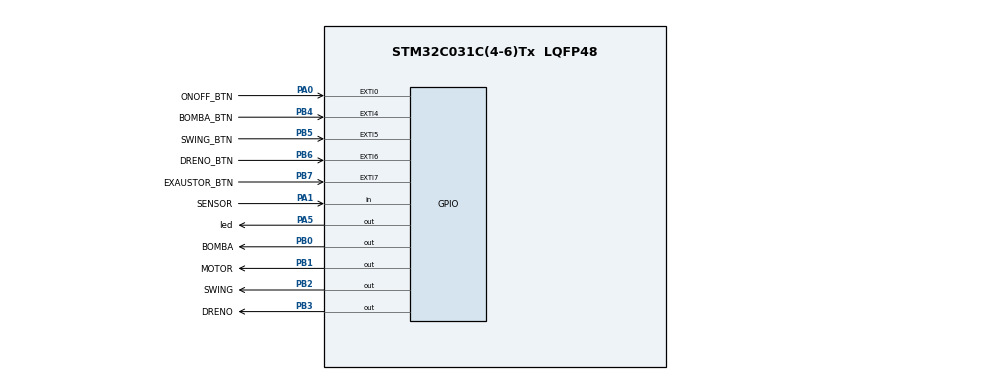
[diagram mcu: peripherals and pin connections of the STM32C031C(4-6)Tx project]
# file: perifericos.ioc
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Mcu.Family=STM32C0
Mcu.Name=STM32C031C(4-6)Tx
Mcu.Package=LQFP48
NVIC.EXTI0_1_IRQn=true\:0\:0\:false\:false\:true\:true\:true\:true
NVIC.EXTI4_15_IRQn=true\:0\:0\:false\:false\:true\:true\:true\:true
NVIC.TIM14_IRQn=true\:0\:0\:false\:false\:true\:true\:true\:true
PA0.GPIO_Label=ONOFF_BTN
PA0.GPIO_PuPd=GPIO_PULLDOWN
PA0.Signal=GPXTI0
PA1.GPIO_Label=SENSOR
PA1.GPIO_PuPd=GPIO_PULLDOWN
PA1.Signal=GPIO_Input
PA13.GPIO_Label=DEBUG_SWDIO
PA13.Signal=DEBUG_SWDIO
PA14-BOOT0.GPIO_Label=DEBUG_SWCLK
PA14-BOOT0.Signal=DEBUG_SWCLK
PA2.GPIO_Label=VCP_USART2_TX
PA2.Signal=USART2_TX
PA3.GPIO_Label=VCP_USART2_RX
PA3.Signal=USART2_RX
PA5.GPIO_Label=led
PA5.GPIO_ModeDefaultOutputPP=GPIO_MODE_OUTPUT_PP
PA5.GPIO_PuPd=GPIO_PULLDOWN
PA5.GPIO_Speed=GPIO_SPEED_FREQ_VERY_HIGH
PA5.Signal=GPIO_Output
PB0.GPIO_Label=BOMBA
PB0.GPIO_PuPd=GPIO_PULLDOWN
PB0.Signal=GPIO_Output
PB1.GPIO_Label=MOTOR
PB1.GPIO_PuPd=GPIO_PULLDOWN
PB1.Signal=GPIO_Output
PB2.GPIO_Label=SWING
PB2.GPIO_PuPd=GPIO_PULLDOWN
PB2.Signal=GPIO_Output
PB3.GPIO_Label=DRENO
PB3.GPIO_PuPd=GPIO_PULLDOWN
PB3.Signal=GPIO_Output
PB4.GPIO_Label=BOMBA_BTN
PB4.GPIO_PuPd=GPIO_PULLDOWN
PB4.Signal=GPXTI4
PB5.GPIO_Label=SWING_BTN
PB5.GPIO_PuPd=GPIO_PULLDOWN
PB5.Signal=GPXTI5
PB6.GPIO_Label=DRENO_BTN
PB6.GPIO_PuPd=GPIO_PULLDOWN
PB6.Signal=GPXTI6
PB7.GPIO_Label=EXAUSTOR_BTN
PB7.GPIO_PuPd=GPIO_PULLDOWN
PB7.Signal=GPXTI7
PC14-OSCX_IN\ (PC14).GPIO_Label=RCC_OSCX_IN
PC14-OSCX_IN\ (PC14).Mode=LSE-External-Oscillator
PC14-OSCX_IN\ (PC14).Signal=RCC_OSCX_IN
PC15-OSCX_OUT\ (PC15).GPIO_Label=RCC_OSCX_OUT
PC15-OSCX_OUT\ (PC15).Mode=LSE-External-Oscillator
PC15-OSCX_OUT\ (PC15).Signal=RCC_OSCX_OUT
PF0-OSC_IN\ (PF0).GPIO_Label=RCC_OSC_IN
PF0-OSC_IN\ (PF0).Signal=RCC_OSC_IN
PF1-OSC_OUT\ (PF1).GPIO_Label=RCC_OSC_OUT
PF1-OSC_OUT\ (PF1).Signal=RCC_OSC_OUT
ProjectManager.HeapSize=0x200
ProjectManager.StackSize=0x400
ProjectManager.TargetToolchain=STM32CubeIDE
RCC.ADCFreq_Value=48000000
RCC.AHBFreq_Value=48000000
RCC.CortexFreq_Value=48000000
RCC.EXTERNAL_CLOCK_VALUE=12288000
RCC.HCLKFreq_Value=48000000
RCC.HSE_VALUE=48000000
RCC.HSISYSCLKDivider=RCC_HSI_DIV1
RCC.HSI_VALUE=48000000
RCC.SYSCLKFreq_VALUE=48000000
TIM14.Period=1000-1
TIM14.Prescaler=48000-1
VP_TIM14_VS_ClockSourceINT.Mode=Enable_Timer
board=NUCLEO-C031C6

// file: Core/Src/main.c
/* USER CODE BEGIN Header */
/**
  ******************************************************************************
  * @file           : main.c
  * @brief          : Main program body
  ******************************************************************************
  * @attention
  *
  * Copyright (c) 2025 STMicroelectronics.
  * All rights reserved.
  *
  * This software is licensed under terms that can be found in the LICENSE file
  * in the root directory of this software component.
  * If no LICENSE file comes with this software, it is provided AS-IS.
  *
  * Os periféricos aqui foram configurados da seguinte forma:
  *
  * 	BOMBA:		OutPut Push Pull, PullDown
  * 	SWING:		OutPut Push Pull, PullDown
  * 	DRENO:		OutPut Push Pull, PullDown
  * 	SENSOR:		Input, PullDown Aqui----->>>>>
  * 	Segunda mudança ---------------------------------------------------------->>>>>>>
  ******************************************************************************
  */
/* USER CODE END Header */
#include "main.h"
#include "tim.h"
#include "gpio.h"

/* USER CODE BEGIN Includes */
#include "perifericos.h"
/* USER CODE END Includes */

void SystemClock_Config(void);

int main(void)
{

  /* MCU Configuration--------------------------------------------------------*/

  /* Reset of all peripherals, Initializes the Flash interface and the Systick. */
  HAL_Init();

  /* Configure the system clock */
  SystemClock_Config();

  /* Initialize all configured peripherals */
  MX_GPIO_Init();
  MX_TIM14_Init();
  /* USER CODE BEGIN 2 */
  /*
   * @Brief: Para utilizar os periféricos, é necessário uma base de tempo de 1 minuto (60s). Para isso, foi utilizado o TIM14
   * que é um timer de uso geral com as seguintes configurações:
   * Clock: 48MHz (HSISYS)
   * Preescaler: 48000 - 1
   * ARR: 60000-1
   */
  HAL_TIM_Base_Start_IT(&htim14);	// Aqui é necessário dar start no timer
  perifericos_set();				// Aqui é chamada a função que carrega os parâmetros setados
  /* USER CODE END 2 */

  /* Infinite loop */
  /* USER CODE BEGIN WHILE */
  while (1)
  {
	  perifericos_task();			// No Loop, apenas é necessário chamar a função de controla e monitora os periféricos
    /* USER CODE END WHILE */

  }
}

void SystemClock_Config(void)
{
  RCC_OscInitTypeDef RCC_OscInitStruct = {0};
  RCC_ClkInitTypeDef RCC_ClkInitStruct = {0};

  __HAL_FLASH_SET_LATENCY(FLASH_LATENCY_1);

  /** Initializes the RCC Oscillators according to the specified parameters
  * in the RCC_OscInitTypeDef structure.
  */
  RCC_OscInitStruct.OscillatorType = RCC_OSCILLATORTYPE_HSI;
  RCC_OscInitStruct.HSIState = RCC_HSI_ON;
  RCC_OscInitStruct.HSIDiv = RCC_HSI_DIV1;
  RCC_OscInitStruct.HSICalibrationValue = RCC_HSICALIBRATION_DEFAULT;
  if (HAL_RCC_OscConfig(&RCC_OscInitStruct) != HAL_OK)
  {
    Error_Handler();
  }

  /** Initializes the CPU, AHB and APB buses clocks
  */
  RCC_ClkInitStruct.ClockType = RCC_CLOCKTYPE_HCLK|RCC_CLOCKTYPE_SYSCLK
                              |RCC_CLOCKTYPE_PCLK1;
  RCC_ClkInitStruct.SYSCLKSource = RCC_SYSCLKSOURCE_HSI;
  RCC_ClkInitStruct.SYSCLKDivider = RCC_SYSCLK_DIV1;
  RCC_ClkInitStruct.AHBCLKDivider = RCC_HCLK_DIV1;
  RCC_ClkInitStruct.APB1CLKDivider = RCC_APB1_DIV1;

  if (HAL_RCC_ClockConfig(&RCC_ClkInitStruct, FLASH_LATENCY_1) != HAL_OK)
  {
    Error_Handler();
  }
}

/* USER CODE BEGIN 4 */
//======================================================Callback do Timer=================================
void HAL_TIM_PeriodElapsedCallback(TIM_HandleTypeDef *htim)
{
    if (htim->Instance == TIM14)
    {
    	perifericos_tick();
    }
}
/* USER CODE END 4 */

void Error_Handler(void)
{
  __disable_irq();
  while (1)
  {
  }
}
